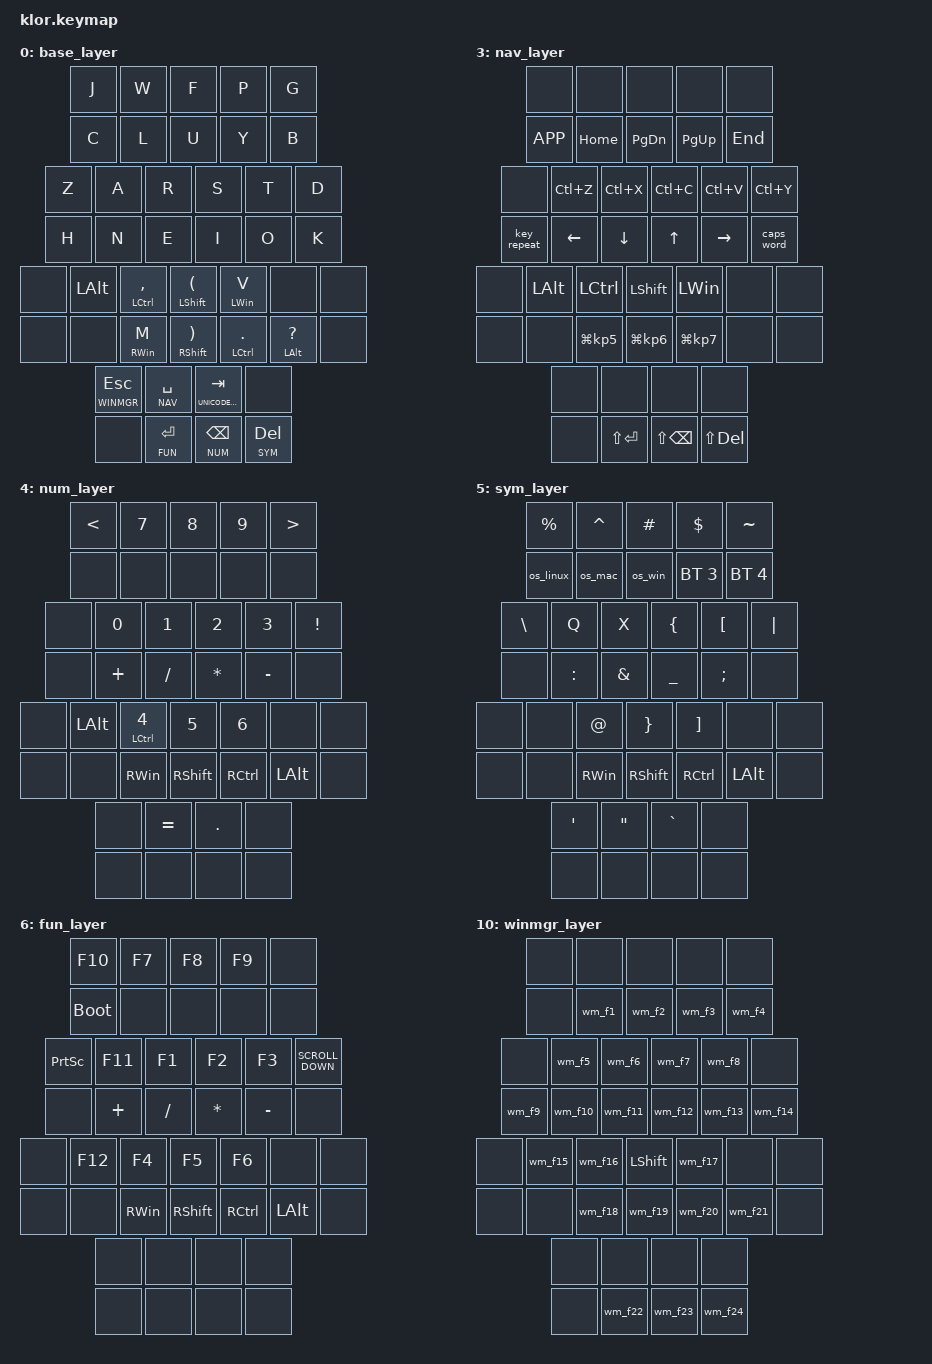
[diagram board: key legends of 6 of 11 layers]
//                               █         █    █            ▄▄▄▀▀▀▀▀▀▄▄▄        █▀▀▀▀▀▀▀▀▀▀█
//                               █        █     █          ▄▀            ▀▄      █          █
//                               █       █      █        ▄▀                ▀▄    █          █
//                               █      █       █        █                  █    █          █
//                               █     █        █       █                    █   █          █
//                               █    █         █       █                    █   █▄▄▄▄▄▄▄▄▄▄█
//                               █   █ █        █       █                    █   █      █
//                               █  █   █       █        █                  █    █       █
//                               █ █     █      █        ▀▄                ▄▀    █        █
//                               ██       █     █          ▀▄            ▄▀      █         █
//                               █         █    █▄▄▄▄▄▄▄▄    ▀▀▀▄▄▄▄▄▄▀▀▀        █          █
//
// ▄▄▄▄▄▄▄▄▄▄▄▄▄▄▄▄▄▄▄▄▄▄▄▄▄▄▄▄▄▄▄▄▄▄▄▄▄▄▄▄▄▄▄▄▄▄▄▄▄▄▄▄▄▄▄▄▄▄▄▄▄▄▄▄▄▄▄▄▄▄▄▄▄▄▄▄▄▄▄▄▄▄▄▄▄▄▄▄▄▄▄▄▄▄▄▄▄▄▄▄▄▄▄▄▄▄▄▄▄▄▄▄▄▄▄▄▄▄▄▄▄▄▄▄▄
       
#include <behaviors.dtsi>
#include <dt-bindings/zmk/keys.h>
#include <dt-bindings/zmk/bt.h>
#include <dt-bindings/zmk/outputs.h>
#include <dt-bindings/zmk/ext_power.h>
#include <dt-bindings/zmk/rgb.h>
#include "unicode.h"


#define BASE    0
#define BASE_MAC 1
#define BASE_WIN 2
#define NAV     3
#define NUM     4
#define SYM     5
#define FUN     6
#define UNICODE_LINUX  7
#define UNICODE_MAC 8
#define UNICODE_WIN 9
#define WINMGR  10

CZECH_PAIR(a_acu,   N0, E, N1,    N0, C, N1)
CZECH_PAIR(e_acu,   N0, E, N9,    N0, C, N9)
CZECH_PAIR(e_car,   N1, N1, B,    N1, N1, A)
CZECH_PAIR(i_acu,   N0, E, D,     N0, C, D)
CZECH_PAIR(o_acu,   N0, F, N3,    N0, D, N3)
CZECH_PAIR(u_acu,   N0, F, A,     N0, D, A)
CZECH_PAIR(u_ring,  N1, N6, F,    N1, N6, E)
CZECH_PAIR(y_acu,   N0, F, D,     N0, D, D)
CZECH_PAIR(c_car,   N1, N0, D,    N1, N0, C)
CZECH_PAIR(d_car,   N1, N0, F,    N1, N0, E)
CZECH_PAIR(n_car,   N1, N4, N8,   N1, N4, N7)
CZECH_PAIR(r_car,   N1, N5, N9,   N1, N5, N8)
CZECH_PAIR(s_car,   N1, N6, N1,   N1, N6, N0)
CZECH_PAIR(t_car,   N1, N6, N5,   N1, N6, N4)
CZECH_PAIR(z_car,   N1, N7, E,    N1, N7, D)

EMOJI_PAIR(emj_smile,      N6, N4, N2,  N6, N0, N2,     D, E,    D, E)
EMOJI_PAIR(emj_grin,       N6, N0, N1,  N6, N0, N5,     D, E,    D, E)
EMOJI_PAIR(emj_sad,        N6, N4, N1,  N6, N2, D,      D, E,    D, E)
EMOJI_PAIR(emj_tongue,     N6, N0, B,   N6, N1, D,      D, E,    D, E)
EMOJI_PAIR(emj_innocent,   N6, N0, N7,  N9, N7, A,      D, E,    E, D)
EMOJI_PAIR(emj_vomit,      N9, N2, N8,  N9, N2, E,      E, D,    E, D)
EMOJI_PAIR(emj_thumb,      N4, N4, D,   N9, N7, N0,     D, C,    E, D)

UNICODE_CHAR(euro, &kp N2 &kp N0 &kp A &kp C, &kp N2 &kp N0 &kp A &kp C)
UNICODE_CHAR(degree, &kp N0 &kp B &kp N0, &kp N0 &kp N0 &kp B &kp N0)
UNICODE_CHAR(crab, &kp N1 &kp F &kp N9 &kp N8 &kp N0, &kp D &kp N8 &kp N3 &kp E &kp D &kp D &kp N8 &kp N0)

OS_HINT_MACRO(l, L, N, X)
OS_HINT_MACRO(m, M, A, C)
OS_HINT_MACRO(w, W, I, N)

// Win Mgr layer
// using just regular mod keys (e.g. LG) without the macro approach did not work as the niri doesn't like the timing
WIN_MGR_MACRO(wm_f1, F1)
WIN_MGR_MACRO(wm_f2, F2)
WIN_MGR_MACRO(wm_f3, F3)
WIN_MGR_MACRO(wm_f4, F4)
WIN_MGR_MACRO(wm_f5, F5)
WIN_MGR_MACRO(wm_f6, F6)
WIN_MGR_MACRO(wm_f7, F7)
WIN_MGR_MACRO(wm_f8, F8)
WIN_MGR_MACRO(wm_f9, F9)
WIN_MGR_MACRO(wm_f10, F10)
WIN_MGR_MACRO(wm_f11, F11)
WIN_MGR_MACRO(wm_f12, F12)
WIN_MGR_MACRO(wm_f13, F13)
WIN_MGR_MACRO(wm_f14, F14)
WIN_MGR_MACRO(wm_f15, F15)
WIN_MGR_MACRO(wm_f16, F16)
WIN_MGR_MACRO(wm_f17, F17)
WIN_MGR_MACRO(wm_f18, F18)
WIN_MGR_MACRO(wm_f19, F19)
WIN_MGR_MACRO(wm_f20, F20)
WIN_MGR_MACRO(wm_f21, F21)
WIN_MGR_MACRO(wm_f22, F22)
WIN_MGR_MACRO(wm_f23, F23)
WIN_MGR_MACRO(wm_f24, F24)


#define TRIGGER_KEYS_L  \
    0 1 2 3 4 \
    10 11 12 13 14 15 \
    23 24 25 26 \
    36 37 38
#define TRIGGER_KEYS_R  \
    5 6 7 8 9 \
    16 17 18 19 20 21 \
    31 32 33 34 \
    41 42 43


/ {
    behaviors {
        lt: layer_tap {
            compatible = "zmk,behavior-hold-tap";
            #binding-cells = <2>;
            flavor = "balanced";
            tapping-term-ms = <200>;
            require-prior-idle-ms = <0>;
            bindings = <&mo>, <&kp>;
        };

        // Home Row Mods
        HRM(hrml, balanced, kp, kp, TRIGGER_KEYS_R)
        HRM(hrmr, balanced, kp, kp, TRIGGER_KEYS_L)
        // Home Row Mods - hold-preferred
        HRM(hrmhl, hold-preferred, kp, kp, TRIGGER_KEYS_R)
        HRM(hrmhr, hold-preferred, kp, kp, TRIGGER_KEYS_L)
        // Home Row Mods - sticky tap
        HRM(hrmsl, balanced, hrm_st, kp, TRIGGER_KEYS_R)
        HRM(hrmsr, balanced, hrm_st, kp, TRIGGER_KEYS_L)
        hrm_st: hrm_sticky_tap {
            compatible = "zmk,behavior-sticky-key";
            #binding-cells = <1>;
            bindings = <&kp>;
            release-after-ms = <1>;
            lazy;            
        };

        tl_on: toggle_layer_on {
            compatible = "zmk,behavior-toggle-layer";
            #binding-cells = <1>;
            toggle-mode = "on";
        };
        tl_off: toggle_layer_off {
            compatible = "zmk,behavior-toggle-layer";
            #binding-cells = <1>;
            toggle-mode = "off";
        };
    };

    macros {
        os_linux: os_linux {
            compatible = "zmk,behavior-macro";
            #binding-cells = <0>;
            wait-ms = <0>;
            tap-ms = <0>;
            bindings = <&tl_off BASE_MAC &tl_off BASE_WIN &bt BT_SEL 0>;
        };
        os_mac: os_mac {
            compatible = "zmk,behavior-macro";
            #binding-cells = <0>;
            wait-ms = <0>;
            tap-ms = <0>;
            bindings = <&tl_on BASE_MAC &tl_off BASE_WIN &bt BT_SEL 1>;
        };
        os_win: os_win {
            compatible = "zmk,behavior-macro";
            #binding-cells = <0>;
            wait-ms = <0>;
            tap-ms = <0>;
            bindings = <&tl_off BASE_MAC &tl_on BASE_WIN &bt BT_SEL 2>;
        };
    };

    conditional_layers {
        compatible = "zmk,conditional-layers";
        czech_mac {
            if-layers = <BASE_MAC UNICODE_LINUX>;
            then-layer = <UNICODE_MAC>;
        };
        czech_win {
            if-layers = <BASE_WIN UNICODE_LINUX>;
            then-layer = <UNICODE_WIN>;
        };
    };

    keymap {
        compatible = "zmk,keymap";

        // ##############################

        base_layer {
            bindings = <
                     &kp J   &kp W   &kp F   &kp P   &kp G
                     &kp C   &kp L   &kp U   &kp Y   &kp B

             &kp Z   &kp A   &kp R   &kp S   &kp T   &kp D
             &kp H   &kp N   &kp E   &kp I   &kp O   &kp K 

             &none   &kp LALT   &hrml LCTRL COMMA    &hrmhl LSHFT LPAR    &hrmsl LWIN V    &none    &none
             &none   &none      &hrmsr RWIN M         &hrmhr RSHFT RPAR    &hrmr LCTRL DOT   &hrmsr LALT QMARK    &none

                                                   &lt WINMGR ESC    &lt NAV SPC     &lt UNICODE_LINUX TAB         &none
                                                   &none             &lt FUN ENTER   &lt NUM BACKSPACE &lt SYM DELETE   
            >;
        };

        // ##############################

        mac_base_layer {
            bindings = <
                BASE_OS_LAYER() 
            >;
        };

        // ##############################

        win_base_layer {
            bindings = <
                BASE_OS_LAYER()
            >;
        };

        // ##############################

        nav_layer {
            bindings = <
                     &none       &none      &none       &none       &none
                     &kp K_APP   &kp HOME   &kp PG_DN   &kp PG_UP   &kp END

             &none   &kp LC(Z)   &kp LC(X)   &kp LC(C)   &kp LC(V)   &kp LC(Y)
             &key_repeat   &kp LEFT      &kp DOWN    &kp UP    &kp RIGHT   &caps_word 

             &none   &kp LALT   &kp LCTRL       &kp LSHFT       &kp LWIN        &none   &none
             &none   &none      &kp LG(KP_N5)   &kp LG(KP_N6)   &kp LG(KP_N7)   &none   &none

                                                   &none   &none           &none               &none
                                                   &none   &kp LS(ENTER)   &kp LS(BACKSPACE)   &kp LS(DELETE)   
            >;
        };

        // ##############################

        num_layer {
            bindings = <
                     &kp LT   &kp N7   &kp N8   &kp N9   &kp GT
                     &none    &none    &none    &none    &none

             &none   &kp N0     &kp N1      &kp N2         &kp N3      &kp EXCL
             &none   &kp PLUS   &kp SLASH   &kp ASTERISK   &kp MINUS   &none
             
             &none   &kp LALT   &hrml LCTRL N4   &kp N5      &kp N6      &none      &none
             &none   &none      &kp RWIN       &kp RSHFT   &kp RCTRL   &kp LALT   &none
                                                   // todo: use
                                                   &none   &kp EQUAL   &kp DOT  &none
                                                   &none   &none       &none    &none   
            >;
        };

        // ##############################

        sym_layer {
            bindings = <                                           
                     &kp PERCENT   &kp CARET   &kp HASH   &kp DOLLAR      &kp TILDE
                     &os_linux     &os_mac   &os_win  &bt BT_SEL 3   &bt BT_SEL 4

             &kp BACKSLASH   &kp Q       &kp X           &kp LEFT_BRACE   &kp LEFT_BRACKET   &kp PIPE
             &none           &kp COLON   &kp AMPERSAND   &kp UNDERSCORE   &kp SEMICOLON      &none
                     //todo: unicode - degree
             &none   &none   &kp AT     &kp RIGHT_BRACE   &kp RIGHT_BRACKET   &none      &none
             &none   &none   &kp RWIN   &kp RSHFT         &kp RCTRL           &kp LALT   &none
                                                   
                                                   &kp SINGLE_QUOTE   &kp DOUBLE_QUOTES   &kp GRAVE  &none
                                                   &none              &none               &none      &none    
            >;
        };

        // ##############################

        fun_layer {
            bindings = <
                     &kp F10   &kp F7   &kp F8   &kp F9   &none
                     &bootloader     &none    &none    &none    &none

             &kp PRINTSCREEN   &kp F11   &kp F1   &kp F2   &kp F3   &kp K_SCROLL_DOWN
             &none   &kp PLUS   &kp SLASH   &kp ASTERISK   &kp MINUS   &none
             
             &none   &kp F12   &kp F4     &kp F5      &kp F6      &none      &none
             &none   &none     &kp RWIN   &kp RSHFT   &kp RCTRL   &kp LALT   &none
                                                   // todo: use all these
                                                   &none   &none   &none   &none
                                                   &none   &none   &none   &none    
            >;
        };

        // ##############################

        linux_unicode_layer {
            bindings = <
                UNICODE_LAYER(l_)   
            >;
        };

        // ##############################

        mac_unicode_layer {
            bindings = <
                UNICODE_LAYER(m_)   
            >;
        };

        // ##############################

        win_unicode_layer {
            bindings = <
                UNICODE_LAYER(w_)   
            >;
        };

        // ##############################

        winmgr_layer {
            bindings = <
                     &none   &none   &none   &none   &none
                     &none   &wm_f1       &wm_f2   &wm_f3   &wm_f4

             &none       &wm_f5   &wm_f6   &wm_f7   &wm_f8   &none
             &wm_f9   &wm_f10       &wm_f11       &wm_f12       &wm_f13       &wm_f14
             
             &none   &wm_f15   &wm_f16   &kp LSHFT   &wm_f17   &none   &none
             &none   &none     &wm_f18   &wm_f19   &wm_f20   &wm_f21   &none
                                                   
                                                   &none   &none   &none         &none
                                                   // todo: 
                                                   &none   &wm_f22   &wm_f23   &wm_f24    
            >;
        };
    };
};
